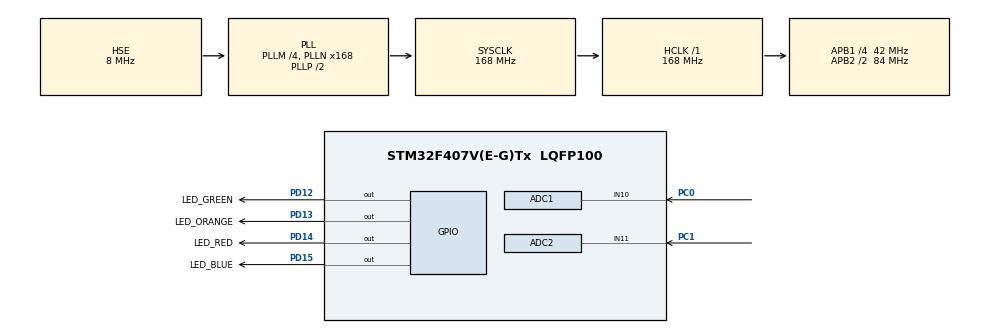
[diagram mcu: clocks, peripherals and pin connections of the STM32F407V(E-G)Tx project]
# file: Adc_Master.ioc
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ADC1.Channel-0\#ChannelRegularConversion=ADC_CHANNEL_10
ADC1.NbrOfConversionFlag=1
ADC1.Rank-0\#ChannelRegularConversion=1
ADC1.SamplingTime-0\#ChannelRegularConversion=ADC_SAMPLETIME_3CYCLES
ADC1.master=1
ADC2.Channel-0\#ChannelRegularConversion=ADC_CHANNEL_11
ADC2.NbrOfConversionFlag=1
ADC2.Rank-0\#ChannelRegularConversion=1
ADC2.SamplingTime-0\#ChannelRegularConversion=ADC_SAMPLETIME_3CYCLES
Mcu.Family=STM32F4
Mcu.Name=STM32F407V(E-G)Tx
Mcu.Package=LQFP100
NVIC.PriorityGroup=NVIC_PRIORITYGROUP_4
NVIC.TIM6_DAC_IRQn=true\:0\:0\:false\:false\:true\:true\:true
PC0.Signal=ADCx_IN10
PC1.Signal=ADCx_IN11
PD12.GPIO_Label=LED_GREEN
PD12.Signal=GPIO_Output
PD13.GPIO_Label=LED_ORANGE
PD13.Signal=GPIO_Output
PD14.GPIO_Label=LED_RED
PD14.Signal=GPIO_Output
PD15.GPIO_Label=LED_BLUE
PD15.Signal=GPIO_Output
PH0-OSC_IN.Mode=HSE-External-Oscillator
PH0-OSC_IN.Signal=RCC_OSC_IN
PH1-OSC_OUT.Mode=HSE-External-Oscillator
PH1-OSC_OUT.Signal=RCC_OSC_OUT
ProjectManager.HeapSize=0x200
ProjectManager.StackSize=0x400
ProjectManager.TargetToolchain=TrueSTUDIO
RCC.48MHZClocksFreq_Value=84000000
RCC.AHBFreq_Value=168000000
RCC.APB1CLKDivider=RCC_HCLK_DIV4
RCC.APB1Freq_Value=42000000
RCC.APB1TimFreq_Value=84000000
RCC.APB2CLKDivider=RCC_HCLK_DIV2
RCC.APB2Freq_Value=84000000
RCC.APB2TimFreq_Value=168000000
RCC.CortexFreq_Value=168000000
RCC.HCLKFreq_Value=168000000
RCC.HSE_VALUE=8000000
RCC.HSI_VALUE=16000000
RCC.LSE_VALUE=32768
RCC.PLLM=4
RCC.PLLN=168
RCC.PLLSourceVirtual=RCC_PLLSOURCE_HSE
RCC.SYSCLKFreq_VALUE=168000000
RCC.SYSCLKSource=RCC_SYSCLKSOURCE_PLLCLK
RCC.VCOOutputFreq_Value=336000000
SH.ADCx_IN10.0=ADC1_IN10,IN10
SH.ADCx_IN11.0=ADC2_IN11,IN11
TIM6.Period=4-1
TIM6.Prescaler=8400
TIM6.TIM_MasterOutputTrigger=TIM_TRGO_UPDATE
VP_TIM6_VS_ClockSourceINT.Mode=Enable_Timer
board=custom

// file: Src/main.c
/* USER CODE BEGIN Header */
/**
  ******************************************************************************
  * @file           : main.c
  * @brief          : Main program body
  ******************************************************************************
  * @attention
  *
  * <h2><center>&copy; Copyright (c) 2020 STMicroelectronics.
  * All rights reserved.</center></h2>
  *
  * This software component is licensed by ST under BSD 3-Clause license,
  * the "License"; You may not use this file except in compliance with the
  * License. You may obtain a copy of the License at:
  *                        opensource.org/licenses/BSD-3-Clause
  *
  ******************************************************************************
  */
/* USER CODE END Header */

#include "main.h"

/* USER CODE BEGIN Includes */
#include "elecParamCalc.h"
/* USER CODE END Includes */

/* USER CODE BEGIN PD */
#define SAMPLE_NUM  200

/* USER CODE END PD */

ADC_HandleTypeDef hadc1;
ADC_HandleTypeDef hadc2;

TIM_HandleTypeDef htim6;

void SystemClock_Config(void);
static void MX_GPIO_Init(void);
static void MX_ADC1_Init(void);
static void MX_ADC2_Init(void);
static void MX_TIM6_Init(void);

/* USER CODE BEGIN 0 */

/*  Lcd data array and update lcd counter. */
char str[20];
char buf[20];
uint8_t lcd_UpdateCounter=0;

/* Adc array data counter. */
int i=0;

/* Adc data array and adc value. */
uint16_t ADC_DATA1,ADC_DATA2;
float channel_voltage[200],channel_voltage_2[200];

void HAL_TIM_PeriodElapsedCallback(TIM_HandleTypeDef *htim)
{

	/* ADC Start. */
	HAL_ADC_Start(&hadc1);
	HAL_ADC_Start(&hadc2);

	/* ADC Get Value.  */
	HAL_ADC_PollForConversion(&hadc1,1);
	ADC_DATA1=HAL_ADC_GetValue(&hadc1);

	HAL_ADC_PollForConversion(&hadc2,1);
	ADC_DATA2=HAL_ADC_GetValue(&hadc2);

	/*  ADC is stopped. */
	HAL_ADC_Stop(&hadc1);
	HAL_ADC_Stop(&hadc2);

	/* Adc value convert to voltage. */
	channel_voltage[i]=(ADC_DATA1*(float)3)/4095;
	channel_voltage_2[i]=((ADC_DATA2*(float)3)/4095)-0.03;

	/* Adc data is get array in SAMPLE_NUM. */
		if(i<SAMPLE_NUM )
		i++;

		else
		{
			i=0;
			HAL_TIM_Base_Stop_IT(&htim6);
			elecParamCalc_Voltage(channel_voltage);
			elecParamCalc_Current(channel_voltage_2);
		}

}

int main(void)
{
  /* MCU Configuration--------------------------------------------------------*/

  /* Reset of all peripherals, Initializes the Flash interface and the Systick. */
  HAL_Init();

  /* Configure the system clock */
  SystemClock_Config();

  /* Initialize all configured peripherals */
  MX_GPIO_Init();
  MX_ADC1_Init();
  MX_ADC2_Init();
  MX_TIM6_Init();

  /* USER CODE BEGIN 2 */

  /*LCD Port Init */
	SET_BIT(RCC->AHB1ENR,RCC_AHB1ENR_GPIOEEN);
	SET_BIT(RCC->AHB1ENR,RCC_AHB1ENR_GPIOBEN);

	GPIOE->MODER =GPIO_MODER_MODER0_0|GPIO_MODER_MODER1_0;
	GPIOB->MODER =GPIO_MODER_MODER0_0|GPIO_MODER_MODER1_0|GPIO_MODER_MODER2_0|GPIO_MODER_MODER3_0;

	/* Lcd Init */
	LCD_Init();
	LCD_Clear();

	/* Timer6 Start */
	HAL_TIM_Base_Start_IT(&htim6);

  /* USER CODE END 2 */

  while (1)
  {

  	  	  	  //Calibration if-else.
	 			if(u8_arrCount<10)
	 		 	{
	 				fl_sampleDataArr[u8_arrCount]=g_elec_param_s.fl_voltage;
	 		 		u8_arrCount++;
	 		 		HAL_TIM_Base_Start_IT(&htim6);
	 		 	}

	 			else
	 		 	{
	 					fl_rms_Voltage=elecParamCalc_Calibration(fl_sampleDataArr);
	 					LCD_Init();
	 					lcd_UpdateCounter++;
						u8_arrCount=0;
				}

	 			if(lcd_UpdateCounter==11)
	 			{

					sprintf(buf,"AC VOLT= %.3fV",fl_rms_Voltage );
					LCD_OutString(buf,1);
		 			sprintf(str,"AC AMP = %.2fA",g_elec_param_s.fl_current );
					LCD_OutString(str,2);
					HAL_Delay(1000);
					lcd_UpdateCounter=0;

	 			}

}
}
void SystemClock_Config(void)
{
  RCC_OscInitTypeDef RCC_OscInitStruct = {0};
  RCC_ClkInitTypeDef RCC_ClkInitStruct = {0};

  /** Configure the main internal regulator output voltage
  */
  __HAL_RCC_PWR_CLK_ENABLE();
  __HAL_PWR_VOLTAGESCALING_CONFIG(PWR_REGULATOR_VOLTAGE_SCALE1);
  /** Initializes the CPU, AHB and APB busses clocks
  */
  RCC_OscInitStruct.OscillatorType = RCC_OSCILLATORTYPE_HSE;
  RCC_OscInitStruct.HSEState = RCC_HSE_ON;
  RCC_OscInitStruct.PLL.PLLState = RCC_PLL_ON;
  RCC_OscInitStruct.PLL.PLLSource = RCC_PLLSOURCE_HSE;
  RCC_OscInitStruct.PLL.PLLM = 4;
  RCC_OscInitStruct.PLL.PLLN = 168;
  RCC_OscInitStruct.PLL.PLLP = RCC_PLLP_DIV2;
  RCC_OscInitStruct.PLL.PLLQ = 4;
  if (HAL_RCC_OscConfig(&RCC_OscInitStruct) != HAL_OK)
  {
    Error_Handler();
  }
  /** Initializes the CPU, AHB and APB busses clocks
  */
  RCC_ClkInitStruct.ClockType = RCC_CLOCKTYPE_HCLK|RCC_CLOCKTYPE_SYSCLK
                              |RCC_CLOCKTYPE_PCLK1|RCC_CLOCKTYPE_PCLK2;
  RCC_ClkInitStruct.SYSCLKSource = RCC_SYSCLKSOURCE_PLLCLK;
  RCC_ClkInitStruct.AHBCLKDivider = RCC_SYSCLK_DIV1;
  RCC_ClkInitStruct.APB1CLKDivider = RCC_HCLK_DIV4;
  RCC_ClkInitStruct.APB2CLKDivider = RCC_HCLK_DIV2;

  if (HAL_RCC_ClockConfig(&RCC_ClkInitStruct, FLASH_LATENCY_5) != HAL_OK)
  {
    Error_Handler();
  }
}

static void MX_ADC1_Init(void)
{

  ADC_ChannelConfTypeDef sConfig = {0};

  /** Configure the global features of the ADC (Clock, Resolution, Data Alignment and number of conversion)
  */
  hadc1.Instance = ADC1;
  hadc1.Init.ClockPrescaler = ADC_CLOCK_SYNC_PCLK_DIV2;
  hadc1.Init.Resolution = ADC_RESOLUTION_12B;
  hadc1.Init.ScanConvMode = DISABLE;
  hadc1.Init.ContinuousConvMode = DISABLE;
  hadc1.Init.DiscontinuousConvMode = DISABLE;
  hadc1.Init.ExternalTrigConvEdge = ADC_EXTERNALTRIGCONVEDGE_NONE;
  hadc1.Init.ExternalTrigConv = ADC_SOFTWARE_START;
  hadc1.Init.DataAlign = ADC_DATAALIGN_RIGHT;
  hadc1.Init.NbrOfConversion = 1;
  hadc1.Init.DMAContinuousRequests = DISABLE;
  hadc1.Init.EOCSelection = ADC_EOC_SINGLE_CONV;
  if (HAL_ADC_Init(&hadc1) != HAL_OK)
  {
    Error_Handler();
  }
  /** Configure for the selected ADC regular channel its corresponding rank in the sequencer and its sample time.
  */
  sConfig.Channel = ADC_CHANNEL_10;
  sConfig.Rank = 1;
  sConfig.SamplingTime = ADC_SAMPLETIME_480CYCLES;
  if (HAL_ADC_ConfigChannel(&hadc1, &sConfig) != HAL_OK)
  {
    Error_Handler();
  }

}

static void MX_ADC2_Init(void)
{

  ADC_ChannelConfTypeDef sConfig = {0};

  /** Configure the global features of the ADC (Clock, Resolution, Data Alignment and number of conversion)
  */
  hadc2.Instance = ADC2;
  hadc2.Init.ClockPrescaler = ADC_CLOCK_SYNC_PCLK_DIV2;
  hadc2.Init.Resolution = ADC_RESOLUTION_12B;
  hadc2.Init.ScanConvMode = DISABLE;
  hadc2.Init.ContinuousConvMode = DISABLE;
  hadc2.Init.DiscontinuousConvMode = DISABLE;
  hadc2.Init.ExternalTrigConvEdge = ADC_EXTERNALTRIGCONVEDGE_NONE;
  hadc2.Init.ExternalTrigConv = ADC_SOFTWARE_START;
  hadc2.Init.DataAlign = ADC_DATAALIGN_RIGHT;
  hadc2.Init.NbrOfConversion = 1;
  hadc2.Init.DMAContinuousRequests = DISABLE;
  hadc2.Init.EOCSelection = ADC_EOC_SINGLE_CONV;
  if (HAL_ADC_Init(&hadc2) != HAL_OK)
  {
    Error_Handler();
  }
  /** Configure for the selected ADC regular channel its corresponding rank in the sequencer and its sample time.
  */
  sConfig.Channel = ADC_CHANNEL_11;
  sConfig.Rank = 1;
  sConfig.SamplingTime = ADC_SAMPLETIME_480CYCLES;
  if (HAL_ADC_ConfigChannel(&hadc2, &sConfig) != HAL_OK)
  {
    Error_Handler();
  }

}

static void MX_TIM6_Init(void)
{

  TIM_MasterConfigTypeDef sMasterConfig = {0};

  htim6.Instance = TIM6;
  htim6.Init.Prescaler = 8400-1;
  htim6.Init.CounterMode = TIM_COUNTERMODE_UP;
  htim6.Init.Period = 10-1;
  htim6.Init.AutoReloadPreload = TIM_AUTORELOAD_PRELOAD_DISABLE;
  if (HAL_TIM_Base_Init(&htim6) != HAL_OK)
  {
    Error_Handler();
  }
  sMasterConfig.MasterOutputTrigger = TIM_TRGO_UPDATE;
  sMasterConfig.MasterSlaveMode = TIM_MASTERSLAVEMODE_DISABLE;
  if (HAL_TIMEx_MasterConfigSynchronization(&htim6, &sMasterConfig) != HAL_OK)
  {
    Error_Handler();
  }

}

static void MX_GPIO_Init(void)
{
  GPIO_InitTypeDef GPIO_InitStruct = {0};

  /* GPIO Ports Clock Enable */
  __HAL_RCC_GPIOH_CLK_ENABLE();
  __HAL_RCC_GPIOC_CLK_ENABLE();
  __HAL_RCC_GPIOD_CLK_ENABLE();

  /*Configure GPIO pin Output Level */
  HAL_GPIO_WritePin(GPIOD, LED_GREEN_Pin|LED_ORANGE_Pin|LED_RED_Pin|LED_BLUE_Pin, GPIO_PIN_RESET);

  /*Configure GPIO pins : LED_GREEN_Pin LED_ORANGE_Pin LED_RED_Pin LED_BLUE_Pin */
  GPIO_InitStruct.Pin = LED_GREEN_Pin|LED_ORANGE_Pin|LED_RED_Pin|LED_BLUE_Pin;
  GPIO_InitStruct.Mode = GPIO_MODE_OUTPUT_PP;
  GPIO_InitStruct.Pull = GPIO_NOPULL;
  GPIO_InitStruct.Speed = GPIO_SPEED_FREQ_LOW;
  HAL_GPIO_Init(GPIOD, &GPIO_InitStruct);

}

void Error_Handler(void)
{
}

/************************ (C) COPYRIGHT STMicroelectronics *****END OF FILE****/
